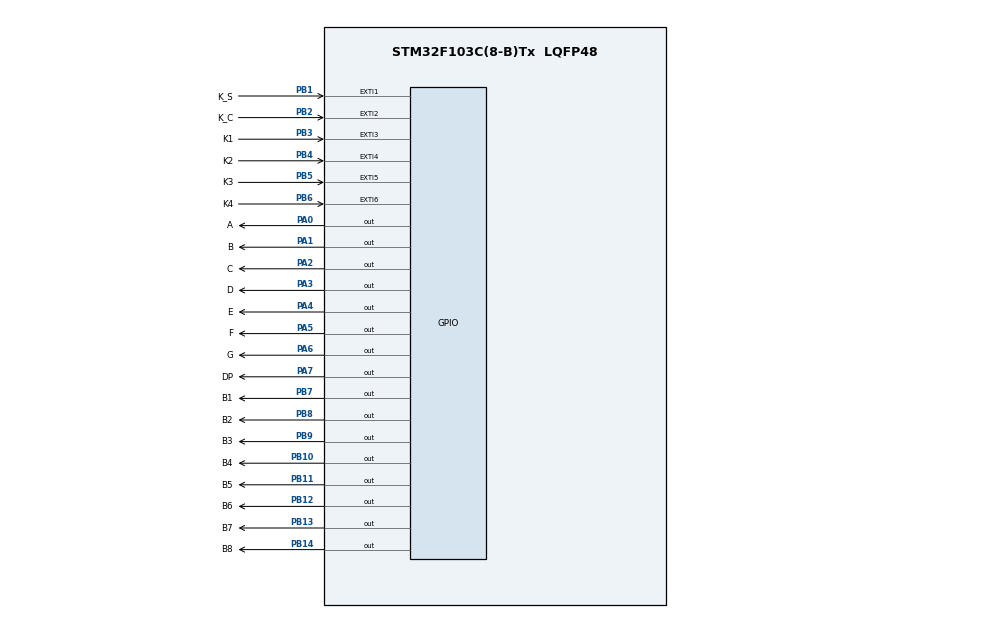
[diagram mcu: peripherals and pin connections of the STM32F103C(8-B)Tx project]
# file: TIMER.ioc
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Mcu.Family=STM32F1
Mcu.Name=STM32F103C(8-B)Tx
Mcu.Package=LQFP48
NVIC.EXTI1_IRQn=true\:0\:0\:true\:false\:true\:true\:true\:true
NVIC.EXTI2_IRQn=true\:0\:0\:true\:false\:true\:true\:true\:true
NVIC.EXTI3_IRQn=true\:0\:0\:true\:false\:true\:true\:true\:true
NVIC.EXTI4_IRQn=true\:0\:0\:true\:false\:true\:true\:true\:true
NVIC.EXTI9_5_IRQn=true\:0\:0\:true\:false\:true\:true\:true\:true
NVIC.PriorityGroup=NVIC_PRIORITYGROUP_4
NVIC.TIM2_IRQn=true\:0\:0\:false\:false\:true\:true\:true\:true
PA0-WKUP.GPIO_Label=A
PA0-WKUP.PinState=GPIO_PIN_SET
PA0-WKUP.Signal=GPIO_Output
PA1.GPIO_Label=B
PA1.PinState=GPIO_PIN_SET
PA1.Signal=GPIO_Output
PA2.GPIO_Label=C
PA2.PinState=GPIO_PIN_SET
PA2.Signal=GPIO_Output
PA3.GPIO_Label=D
PA3.PinState=GPIO_PIN_SET
PA3.Signal=GPIO_Output
PA4.GPIO_Label=E
PA4.PinState=GPIO_PIN_SET
PA4.Signal=GPIO_Output
PA5.GPIO_Label=F
PA5.PinState=GPIO_PIN_SET
PA5.Signal=GPIO_Output
PA6.GPIO_Label=G
PA6.PinState=GPIO_PIN_SET
PA6.Signal=GPIO_Output
PA7.GPIO_Label=DP
PA7.PinState=GPIO_PIN_SET
PA7.Signal=GPIO_Output
PB1.GPIO_Label=K_S
PB1.GPIO_ModeDefaultEXTI=GPIO_MODE_IT_FALLING
PB1.GPIO_PuPd=GPIO_PULLUP
PB1.Signal=GPXTI1
PB10.GPIO_Label=B4
PB10.Signal=GPIO_Output
PB11.GPIO_Label=B5
PB11.Signal=GPIO_Output
PB12.GPIO_Label=B6
PB12.Signal=GPIO_Output
PB13.GPIO_Label=B7
PB13.Signal=GPIO_Output
PB14.GPIO_Label=B8
PB14.Signal=GPIO_Output
PB2.GPIO_Label=K_C
PB2.GPIO_ModeDefaultEXTI=GPIO_MODE_IT_FALLING
PB2.GPIO_PuPd=GPIO_PULLUP
PB2.Signal=GPXTI2
PB3.GPIO_Label=K1
PB3.GPIO_ModeDefaultEXTI=GPIO_MODE_IT_FALLING
PB3.GPIO_PuPd=GPIO_PULLUP
PB3.Signal=GPXTI3
PB4.GPIO_Label=K2
PB4.GPIO_ModeDefaultEXTI=GPIO_MODE_IT_FALLING
PB4.GPIO_PuPd=GPIO_PULLUP
PB4.Signal=GPXTI4
PB5.GPIO_Label=K3
PB5.GPIO_ModeDefaultEXTI=GPIO_MODE_IT_FALLING
PB5.GPIO_PuPd=GPIO_PULLUP
PB5.Signal=GPXTI5
PB6.GPIO_Label=K4
PB6.GPIO_ModeDefaultEXTI=GPIO_MODE_IT_FALLING
PB6.GPIO_PuPd=GPIO_PULLUP
PB6.Signal=GPXTI6
PB7.GPIO_Label=B1
PB7.Signal=GPIO_Output
PB8.GPIO_Label=B2
PB8.Signal=GPIO_Output
PB9.GPIO_Label=B3
PB9.Signal=GPIO_Output
ProjectManager.HeapSize=0x200
ProjectManager.StackSize=0x400
ProjectManager.TargetToolchain=MDK-ARM V5.32
RCC.APB1Freq_Value=8000000
RCC.APB2Freq_Value=8000000
TIM2.Period=10-1
TIM2.Prescaler=8000-1
VP_SYS_VS_ND.Mode=No_Debug
VP_TIM2_VS_ClockSourceINT.Mode=Internal
board=custom

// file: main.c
/* USER CODE BEGIN Header */
/**
  ******************************************************************************
  * @file           : main.c
  * @brief          : Main program body
  ******************************************************************************
  * @attention
  *
  * Copyright (c) 2025 STMicroelectronics.
  * All rights reserved.
  *
  * This software is licensed under terms that can be found in the LICENSE file
  * in the root directory of this software component.
  * If no LICENSE file comes with this software, it is provided AS-IS.
  *
  ******************************************************************************
  */
/* USER CODE END Header */
#include "main.h"
#include "tim.h"
#include "gpio.h"

void SystemClock_Config(void);
/* USER CODE BEGIN PFP */
void Display_clear(void);
void Display_max8(void);
/* USER CODE END PFP */

/* USER CODE BEGIN 0 */
uint16_t hund_num,sec_num,min_num,hour_num;
uint16_t hund_num_set,sec_num_set,min_num_set,hour_num_set;
/* USER CODE END 0 */

int main(void)
{

  /* MCU Configuration--------------------------------------------------------*/

  /* Reset of all peripherals, Initializes the Flash interface and the Systick. */
  HAL_Init();

  /* Configure the system clock */
  SystemClock_Config();

  /* Initialize all configured peripherals */
  MX_GPIO_Init();
  MX_TIM2_Init();
  /* USER CODE BEGIN 2 */
	hund_num=0;
	Display_clear();
	HAL_TIM_Base_Start_IT(&htim2);
  /* USER CODE END 2 */

  /* Infinite loop */
  while (1)
  {
			Display_max8();
  }
}

void SystemClock_Config(void)
{
  RCC_OscInitTypeDef RCC_OscInitStruct = {0};
  RCC_ClkInitTypeDef RCC_ClkInitStruct = {0};

  /** Initializes the RCC Oscillators according to the specified parameters
  * in the RCC_OscInitTypeDef structure.
  */
  RCC_OscInitStruct.OscillatorType = RCC_OSCILLATORTYPE_HSI;
  RCC_OscInitStruct.HSIState = RCC_HSI_ON;
  RCC_OscInitStruct.HSICalibrationValue = RCC_HSICALIBRATION_DEFAULT;
  RCC_OscInitStruct.PLL.PLLState = RCC_PLL_NONE;
  if (HAL_RCC_OscConfig(&RCC_OscInitStruct) != HAL_OK)
  {
    Error_Handler();
  }

  /** Initializes the CPU, AHB and APB buses clocks
  */
  RCC_ClkInitStruct.ClockType = RCC_CLOCKTYPE_HCLK|RCC_CLOCKTYPE_SYSCLK
                              |RCC_CLOCKTYPE_PCLK1|RCC_CLOCKTYPE_PCLK2;
  RCC_ClkInitStruct.SYSCLKSource = RCC_SYSCLKSOURCE_HSI;
  RCC_ClkInitStruct.AHBCLKDivider = RCC_SYSCLK_DIV1;
  RCC_ClkInitStruct.APB1CLKDivider = RCC_HCLK_DIV1;
  RCC_ClkInitStruct.APB2CLKDivider = RCC_HCLK_DIV1;

  if (HAL_RCC_ClockConfig(&RCC_ClkInitStruct, FLASH_LATENCY_0) != HAL_OK)
  {
    Error_Handler();
  }
}

void Error_Handler(void)
{
  __disable_irq();
  while (1)
  {
  }
}
